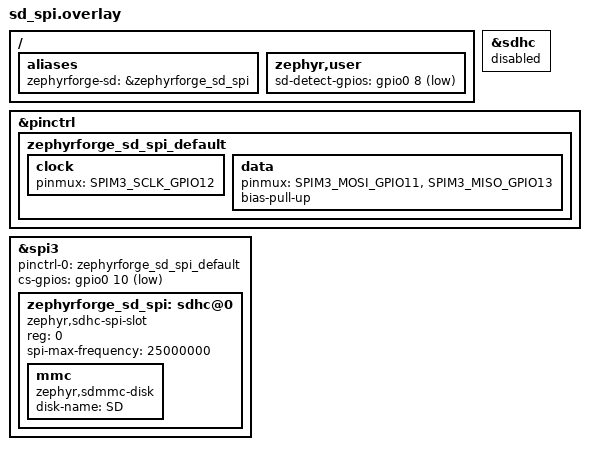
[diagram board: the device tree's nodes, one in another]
/*
 * ESP32-S3 SD over SPI3: GPIO12 SCK, GPIO11 MOSI, GPIO13 MISO, GPIO10 CS, GPIO8 card detect.
 */
#include <zephyr/dt-bindings/gpio/gpio.h>
#include <zephyr/dt-bindings/pinctrl/esp32s3-pinctrl.h>

/ {
	aliases {
		zephyrforge-sd = &zephyrforge_sd_spi;
	};
	zephyr,user {
		sd-detect-gpios = <&gpio0 8 (GPIO_ACTIVE_LOW | GPIO_PULL_UP)>;
	};
};

/* The upstream SoC DTS leaves the native SDHC controller available by default. */
&sdhc {
	status = "disabled";
};

&pinctrl {
	zephyrforge_sd_spi_default: zephyrforge_sd_spi_default {
		clock {
			pinmux = <SPIM3_SCLK_GPIO12>;
		};
		data {
			pinmux = <SPIM3_MOSI_GPIO11>, <SPIM3_MISO_GPIO13>;
			bias-pull-up;
		};
	};
};

/* Override all default SPI3 pins to avoid the module's internal flash/PSRAM signals. */
&spi3 {
	status = "okay";
	pinctrl-0 = <&zephyrforge_sd_spi_default>;
	pinctrl-names = "default";
	cs-gpios = <&gpio0 10 GPIO_ACTIVE_LOW>;
	zephyrforge_sd_spi: sdhc@0 {
		compatible = "zephyr,sdhc-spi-slot";
		reg = <0>;
		spi-max-frequency = <25000000>;
		mmc {
			compatible = "zephyr,sdmmc-disk";
			disk-name = "SD";
			status = "okay";
		};
	};
};
